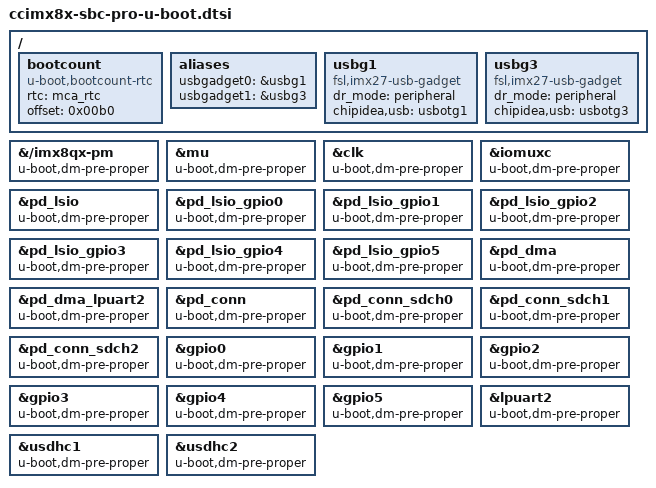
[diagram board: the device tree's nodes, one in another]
// SPDX-License-Identifier: GPL-2.0+
/*
 * Copyright 2020 Digi International Inc.
 */

/ {
	bootcount {
		compatible = "u-boot,bootcount-rtc";
		rtc = <&mca_rtc>;
		offset = <0x00b0>;
	};

	aliases {
		usbgadget0 = &usbg1;
		usbgadget1 = &usbg3;
	};

	usbg1: usbg1 {
		compatible = "fsl,imx27-usb-gadget";
		dr_mode = "peripheral";
		chipidea,usb = <&usbotg1>;
		status = "okay";
		u-boot,dm-spl;
	};

	usbg3: usbg3 {
		compatible = "fsl,imx27-usb-gadget";
		dr_mode = "peripheral";
		chipidea,usb = <&usbotg3>;
		status = "okay";
		u-boot,dm-spl;
	};
};

#ifndef CONFIG_SPL
/*
 * U-Boot specific info for NON-SPL builds
 */
&{/imx8qx-pm} {
	u-boot,dm-pre-proper;
};

&mu {
	u-boot,dm-pre-proper;
};

&clk {
	u-boot,dm-pre-proper;
};

&iomuxc {
	u-boot,dm-pre-proper;
};

&pd_lsio {
	u-boot,dm-pre-proper;
};

&pd_lsio_gpio0 {
	u-boot,dm-pre-proper;
};

&pd_lsio_gpio1 {
	u-boot,dm-pre-proper;
};

&pd_lsio_gpio2 {
	u-boot,dm-pre-proper;
};

&pd_lsio_gpio3 {
	u-boot,dm-pre-proper;
};

&pd_lsio_gpio4 {
	u-boot,dm-pre-proper;
};

&pd_lsio_gpio5 {
	u-boot,dm-pre-proper;
};

&pd_dma {
	u-boot,dm-pre-proper;
};

&pd_dma_lpuart2 {
	u-boot,dm-pre-proper;
};

&pd_conn {
	u-boot,dm-pre-proper;
};

&pd_conn_sdch0 {
	u-boot,dm-pre-proper;
};

&pd_conn_sdch1 {
	u-boot,dm-pre-proper;
};

&pd_conn_sdch2 {
	u-boot,dm-pre-proper;
};

&gpio0 {
	u-boot,dm-pre-proper;
};

&gpio1 {
	u-boot,dm-pre-proper;
};

&gpio2 {
	u-boot,dm-pre-proper;
};

&gpio3 {
	u-boot,dm-pre-proper;
};

&gpio4 {
	u-boot,dm-pre-proper;
};

&gpio5 {
	u-boot,dm-pre-proper;
};

&lpuart2 {
	u-boot,dm-pre-proper;
};

&usdhc1 {
	u-boot,dm-pre-proper;
};

&usdhc2 {
	u-boot,dm-pre-proper;
};

#else

/*
 * U-Boot specific info for SPL builds
 */
&{/imx8qx-pm} {
	u-boot,dm-spl;
};

&mu {
	u-boot,dm-spl;
};

&clk {
	u-boot,dm-spl;
};

&iomuxc {
	u-boot,dm-spl;
};

&pd_lsio {
	u-boot,dm-spl;
};

&pd_lsio_gpio0 {
	u-boot,dm-spl;
};

&pd_lsio_gpio1 {
	u-boot,dm-spl;
};

&pd_lsio_gpio2 {
	u-boot,dm-spl;
};

&pd_lsio_gpio3 {
	u-boot,dm-spl;
};

&pd_lsio_gpio4 {
	u-boot,dm-spl;
};

&pd_lsio_gpio5 {
	u-boot,dm-spl;
};

&pd_lsio_gpio6 {
	u-boot,dm-spl;
};

&pd_lsio_gpio7 {
	u-boot,dm-spl;
};

&pd_dma {
	u-boot,dm-spl;
};

&pd_dma_lpuart2 {
	u-boot,dm-spl;
};

&pd_conn {
	u-boot,dm-spl;
};

&pd_conn_sdch0 {
	u-boot,dm-spl;
};

&pd_conn_sdch1 {
	u-boot,dm-spl;
};

&pd_conn_sdch2 {
	u-boot,dm-spl;
};

&pd_conn_usbotg0 {
	u-boot,dm-spl;
};

&pd_conn_usbotg0_phy {
	u-boot,dm-spl;
};

&pd_conn_usb2 {
	u-boot,dm-spl;
};

&pd_conn_usb2_phy {
	u-boot,dm-spl;
};

&pd_caam {
	u-boot,dm-spl;
};

&pd_caam_jr1 {
	u-boot,dm-spl;
};

&pd_caam_jr2 {
	u-boot,dm-spl;
};

&pd_caam_jr3 {
	u-boot,dm-spl;
};

&gpio0 {
	u-boot,dm-spl;
};

&gpio1 {
	u-boot,dm-spl;
};

&gpio2 {
	u-boot,dm-spl;
};

&gpio3 {
	u-boot,dm-spl;
};

&gpio4 {
	u-boot,dm-spl;
};

&gpio5 {
	u-boot,dm-spl;
};

&gpio6 {
	u-boot,dm-spl;
};

&gpio7 {
	u-boot,dm-spl;
};

&lpuart2 {
	u-boot,dm-spl;
};

&usbmisc1 {
	u-boot,dm-spl;
};

&usbphy1 {
	u-boot,dm-spl;
};

&usbotg1 {
	u-boot,dm-spl;
};

&usbotg3 {
	phys = <&usbphynop1>;
	u-boot,dm-spl;
};

&usbphynop1 {
	compatible = "cdns,usb3-phy";
	reg = <0x0 0x5B160000 0x0 0x40000>;
	#phy-cells = <0>;
	u-boot,dm-spl;
};

&usdhc1 {
	u-boot,dm-spl;
};

&usdhc2 {
	u-boot,dm-spl;
};

&crypto {
	u-boot,dm-spl;
};

&sec_jr1 {
	u-boot,dm-spl;
};

&sec_jr2 {
	u-boot,dm-spl;
};

&sec_jr3 {
	u-boot,dm-spl;
};
#endif
